# STM32L071 register map
File version: 1.3
CPU: CM0+ r0p0, little endian, no MPU, no FPU, 3 interrupt priority bits
Registers are 32-bit, read-write, reset 0x0 unless marked. A register's access mark holds for its fields unless they carry their own. Offsets are from the block's base; [hi:lo] are bit positions.

## LPTIM — Low power timer
Base 0x40007C00
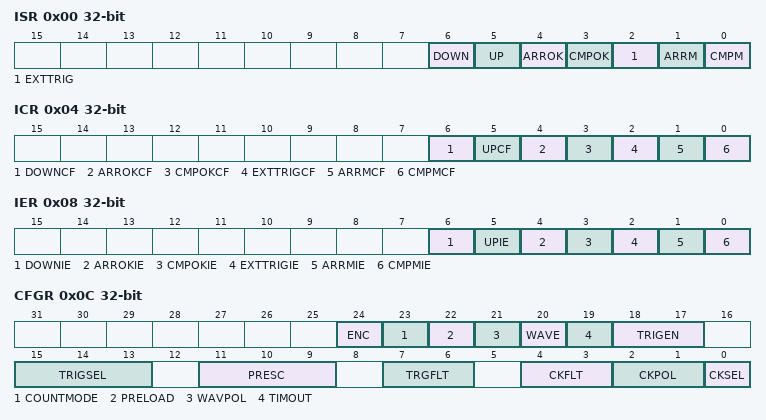
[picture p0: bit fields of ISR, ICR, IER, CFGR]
0x00 ISR ro — Interrupt and Status Register
  [6] DOWN — Counter direction change up to down
  [5] UP — Counter direction change down to up
  [4] ARROK — Autoreload register update OK
  [3] CMPOK — Compare register update OK
  [2] EXTTRIG — External trigger edge event
  [1] ARRM — Autoreload match
  [0] CMPM — Compare match
0x04 ICR wo — Interrupt Clear Register
  [6] DOWNCF — Direction change to down Clear Flag
  [5] UPCF — Direction change to UP Clear Flag
  [4] ARROKCF — Autoreload register update OK Clear Flag
  [3] CMPOKCF — Compare register update OK Clear Flag
  [2] EXTTRIGCF — External trigger valid edge Clear Flag
  [1] ARRMCF — Autoreload match Clear Flag
  [0] CMPMCF — compare match Clear Flag
0x08 IER — Interrupt Enable Register
  [6] DOWNIE — Direction change to down Interrupt Enable
  [5] UPIE — Direction change to UP Interrupt Enable
  [4] ARROKIE — Autoreload register update OK Interrupt Enable
  [3] CMPOKIE — Compare register update OK Interrupt Enable
  [2] EXTTRIGIE — External trigger valid edge Interrupt Enable
  [1] ARRMIE — Autoreload match Interrupt Enable
  [0] CMPMIE — Compare match Interrupt Enable
0x0C CFGR — Configuration Register
  [24] ENC — Encoder mode enable
  [23] COUNTMODE — counter mode enabled
  [22] PRELOAD — Registers update mode
  [21] WAVPOL — Waveform shape polarity
  [20] WAVE — Waveform shape
  [19] TIMOUT — Timeout enable
  [18:17] TRIGEN — Trigger enable and polarity
  [15:13] TRIGSEL — Trigger selector
  [11:9] PRESC — Clock prescaler
  [7:6] TRGFLT — Configurable digital filter for trigger
  [4:3] CKFLT — Configurable digital filter for external clock
  [2:1] CKPOL — Clock Polarity
  [0] CKSEL — Clock selector
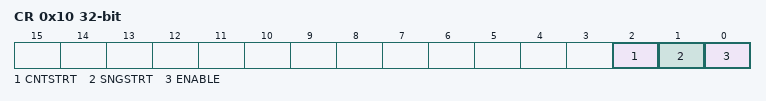
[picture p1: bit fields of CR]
0x10 CR — Control Register
  [2] CNTSTRT — Timer start in continuous mode
  [1] SNGSTRT — LPTIM start in single mode
  [0] ENABLE — LPTIM Enable
0x14 CMP — Compare Register
  [15:0] CMP — Compare value.
0x18 ARR reset 0x1 — Autoreload Register
  [15:0] ARR — Auto reload value.
0x1C CNT ro — Counter Register
  [15:0] CNT — Counter value.

## IWDG — Independent watchdog
Base 0x40003000
0x00 KR wo — Key register
  [15:0] KEY — Key value (write only, read 0x0000)
0x04 PR — Prescaler register
  [2:0] PR — Prescaler divider
0x08 RLR reset 0xFFF — Reload register
  [11:0] RL — Watchdog counter reload value
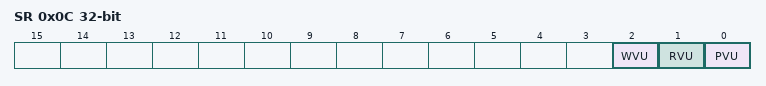
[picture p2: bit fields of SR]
0x0C SR ro — Status register
  [2] WVU — Watchdog counter window value update
  [1] RVU — Watchdog counter reload value update
  [0] PVU — Watchdog prescaler value update
0x10 WINR reset 0xFFF — Window register
  [11:0] WIN — Watchdog counter window value

## WWDG — System window watchdog
Base 0x40002C00
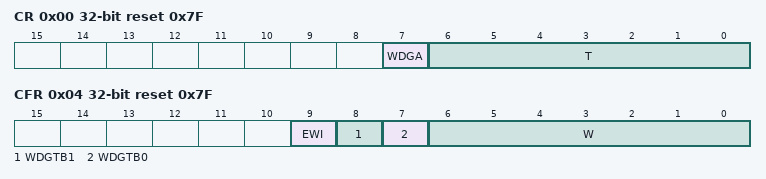
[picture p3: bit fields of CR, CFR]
0x00 CR reset 0x7F — Control register
  [7] WDGA — Activation bit
  [6:0] T — 7-bit counter (MSB to LSB)
0x04 CFR reset 0x7F — Configuration register
  [9] EWI — Early wakeup interrupt
  [8] WDGTB1 — Timer base
  [7] WDGTB0
  [6:0] W — 7-bit window value
0x08 SR — Status register
  [0] EWIF — Early wakeup interrupt flag

## Firewall
Base 0x40011C00
0x00 FIREWALL_CSSA — Code segment start address
  [23:8] ADD — code segment start address
0x04 FIREWALL_CSL — Code segment length
  [21:8] LENG — code segment length
0x08 FIREWALL_NVDSSA — Non-volatile data segment start address
  [23:8] ADD
0x0C FIREWALL_NVDSL — Non-volatile data segment length
  [21:8] LENG
0x10 FIREWALL_VDSSA — Volatile data segment start address
  [15:6] ADD
0x14 FIREWALL_VDSL — Volatile data segment length
  [15:6] LENG — Non-volatile data segment length
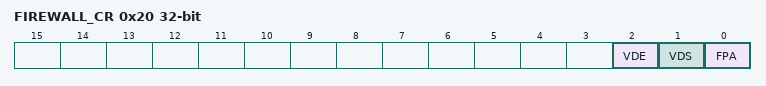
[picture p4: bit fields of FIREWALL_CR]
0x20 FIREWALL_CR — Configuration register
  [2] VDE — Volatile data execution
  [1] VDS — Volatile data shared
  [0] FPA — Firewall pre alarm
